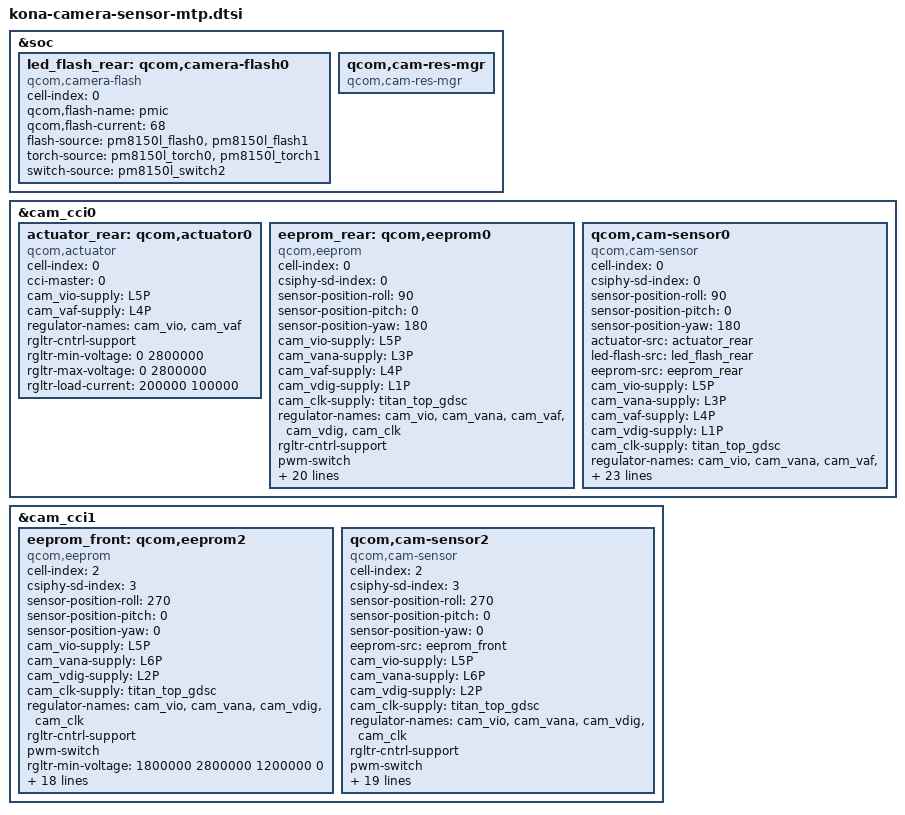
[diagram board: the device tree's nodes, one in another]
#include <dt-bindings/clock/qcom,camcc-kona.h>
&soc {
	led_flash_rear: qcom,camera-flash0 {
		cell-index = <0>;
		compatible = "qcom,camera-flash";
		qcom,flash-name = "pmic";
		qcom,flash-current = <68>;
		flash-source = <&pm8150l_flash0 &pm8150l_flash1>;
		torch-source = <&pm8150l_torch0 &pm8150l_torch1>;
		switch-source = <&pm8150l_switch2>;
		status = "ok";
	};

	qcom,cam-res-mgr {
		compatible = "qcom,cam-res-mgr";
		status = "ok";
	};
};

&cam_cci0 {
	actuator_rear: qcom,actuator0 {
		cell-index = <0>;
		compatible = "qcom,actuator";
		cci-master = <0>;
		cam_vio-supply = <&L5P>;
		cam_vaf-supply = <&L4P>;//<&pm8150a_l9>;
		regulator-names = "cam_vio", "cam_vaf";
		rgltr-cntrl-support;
		rgltr-min-voltage = <0 2800000>;
		rgltr-max-voltage = <0 2800000>;
		rgltr-load-current = <200000 100000>;
	};

	eeprom_rear: qcom,eeprom0 {
		cell-index = <0>;
		compatible = "qcom,eeprom";
		csiphy-sd-index = <0>;
		sensor-position-roll = <90>;
		sensor-position-pitch = <0>;
		sensor-position-yaw = <180>;
		cam_vio-supply = <&L5P>;
		cam_vana-supply = <&L3P>;
		cam_vaf-supply = <&L4P>;
		cam_vdig-supply = <&L1P>;
		cam_clk-supply = <&titan_top_gdsc>;
		regulator-names = "cam_vio", "cam_vana", "cam_vaf", "cam_vdig",
			"cam_clk";
		rgltr-cntrl-support;
		pwm-switch;
		rgltr-min-voltage = <1800000 2800000 2800000 1056000 0>;
		rgltr-max-voltage = <1800000 2800000 2800000 1056000 0>;
		rgltr-load-current = <0 80000 80000 105000 0>;
		gpio-no-mux = <0>;
		pinctrl-names = "cam_default", "cam_suspend";
		pinctrl-0 = <&cam_sensor_mclk0_active
				&cam_sensor_active_rear>;
		pinctrl-1 = <&cam_sensor_mclk0_suspend
				&cam_sensor_suspend_rear>;
		gpios = <&tlmm 94 0>,
			<&tlmm 109 0>;
		gpio-reset = <1>;
		gpio-req-tbl-num = <0 1>;
		gpio-req-tbl-flags = <1 0>;
		gpio-req-tbl-label = "CAMIF_MCLK0",
					"CAM_RESET0";
		sensor-mode = <0>;
		cci-master = <0>;
		status = "ok";
		clocks = <&clock_camcc CAM_CC_MCLK0_CLK>;
		clock-names = "cam_clk";
		clock-cntl-level = "turbo";
		clock-rates = <24000000>;
	};

    /*HI1336*/
	qcom,cam-sensor0 {
		cell-index = <0>;
		compatible = "qcom,cam-sensor";
		csiphy-sd-index = <0>;
		sensor-position-roll = <90>;
		sensor-position-pitch = <0>;
		sensor-position-yaw = <180>;
		actuator-src = <&actuator_rear>;
		led-flash-src = <&led_flash_rear>;
		//ois-src = <&ois_rear>;
		eeprom-src = <&eeprom_rear>;
		cam_vio-supply = <&L5P>;
		cam_vana-supply = <&L3P>;
		cam_vaf-supply = <&L4P>;
		cam_vdig-supply = <&L1P>;
		cam_clk-supply = <&titan_top_gdsc>;
		regulator-names = "cam_vio", "cam_vana", "cam_vaf", "cam_vdig",
			"cam_clk";
		rgltr-cntrl-support;
		pwm-switch;
		rgltr-min-voltage = <1800000 2800000  2800000 1056000 0>;
		rgltr-max-voltage = <1800000 2800000  2800000 1056000 0>;
		rgltr-load-current = <0 80000 80000 105000 0>;
		gpio-no-mux = <0>;
		pinctrl-names = "cam_default", "cam_suspend";
		pinctrl-0 = <&cam_sensor_mclk0_active
				&cam_sensor_active_rear>;
		pinctrl-1 = <&cam_sensor_mclk0_suspend
				&cam_sensor_suspend_rear>;
		gpios = <&tlmm 94 0>,
			<&tlmm 109 0>;
		gpio-reset = <1>;
		gpio-req-tbl-num = <0 1>;
		gpio-req-tbl-flags = <1 0>;
		gpio-req-tbl-label = "CAMIF_MCLK0",
					"CAM_RESET0";
		sensor-mode = <0>;
		cci-master = <0>;
		status = "ok";
		clocks = <&clock_camcc CAM_CC_MCLK0_CLK>;
		clock-names = "cam_clk";
		clock-cntl-level = "turbo";
		clock-rates = <24000000>;
	};
};
// ccix descrip device
&cam_cci1 {
	eeprom_front: qcom,eeprom2 {
		cell-index = <2>;
		compatible = "qcom,eeprom";
		csiphy-sd-index = <3>;
		sensor-position-roll = <270>;
		sensor-position-pitch = <0>;
		sensor-position-yaw = <0>;
		cam_vio-supply = <&L5P>;
		cam_vana-supply = <&L6P>;
		cam_vdig-supply = <&L2P>;
		cam_clk-supply = <&titan_top_gdsc>;
		regulator-names = "cam_vio", "cam_vana", "cam_vdig",
			"cam_clk";
		rgltr-cntrl-support;
		pwm-switch;
		rgltr-min-voltage = <1800000 2800000 1200000 0>;
		rgltr-max-voltage = <1800000 2800000 1200000 0>;
		rgltr-load-current = <0 80000 105000 0>;
		gpio-no-mux = <0>;
		pinctrl-names = "cam_default", "cam_suspend";
		pinctrl-0 = <&cam_sensor_mclk2_active
				 &cam_sensor_active_rst2>;
		pinctrl-1 = <&cam_sensor_mclk2_suspend
				 &cam_sensor_suspend_rst2>;
		gpios = <&tlmm 96 0>,
			<&tlmm 78 0>;
		gpio-reset = <1>;
		gpio-req-tbl-num = <0 1>;
		gpio-req-tbl-flags = <1 0>;
		gpio-req-tbl-label = "CAMIF_MCLK2",
					"CAM_RESET2";
		sensor-mode = <0>;
		cci-device = <0>;
		cci-master = <0>;
		status = "ok";
		clocks = <&clock_camcc CAM_CC_MCLK2_CLK>;
		clock-names = "cam_clk";
		clock-cntl-level = "turbo";
		clock-rates = <24000000>;
	};
    /*hi846*/
	qcom,cam-sensor2 {
		cell-index = <2>;
		compatible = "qcom,cam-sensor";
		csiphy-sd-index = <3>;
		sensor-position-roll = <270>;
		sensor-position-pitch = <0>;
		sensor-position-yaw = <0>;
		eeprom-src = <&eeprom_front>;
		cam_vio-supply = <&L5P>;
		cam_vana-supply = <&L6P>;
		cam_vdig-supply = <&L2P>;
		cam_clk-supply = <&titan_top_gdsc>;
		regulator-names = "cam_vio", "cam_vana", "cam_vdig",
			"cam_clk";
		rgltr-cntrl-support;
		pwm-switch;
		rgltr-min-voltage = <1800000 2800000 1200000 0>;
		rgltr-max-voltage = <1800000 2800000 1200000 0>;
		rgltr-load-current = <0 80000 105000 0>;
		gpio-no-mux = <0>;
		pinctrl-names = "cam_default", "cam_suspend";
		pinctrl-0 = <&cam_sensor_mclk2_active
				 &cam_sensor_active_rst2>;
		pinctrl-1 = <&cam_sensor_mclk2_suspend
				 &cam_sensor_suspend_rst2>;
		gpios = <&tlmm 96 0>,
			<&tlmm 78 0>;
		gpio-reset = <1>;
		gpio-req-tbl-num = <0 1>;
		gpio-req-tbl-flags = <1 0>;
		gpio-req-tbl-label = "CAMIF_MCLK2",
					"CAM_RESET2";
		sensor-mode = <0>;
		cci-device = <0>;
		cci-master = <0>;
		status = "ok";
		clocks = <&clock_camcc CAM_CC_MCLK2_CLK>;
		clock-names = "cam_clk";
		clock-cntl-level = "turbo";
		clock-rates = <24000000>;
	};
};
/*endif */
